AUTOSAR XML (schema 4-0-3)
package /ComponentTypes
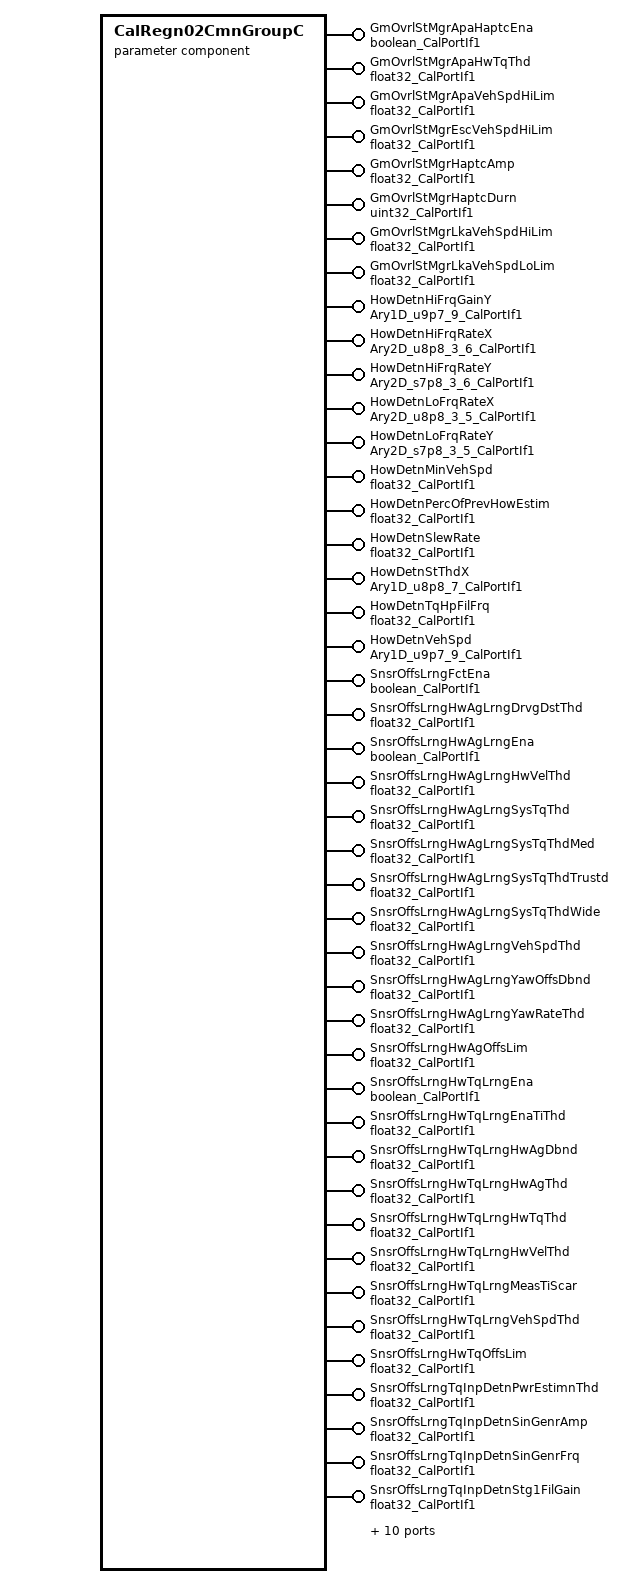
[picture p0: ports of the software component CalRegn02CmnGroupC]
  parameter sw component type CalRegn02CmnGroupC
    54 x provide port:
      GmOvrlStMgrApaHaptcEna: parameter-provide-com-spec{init-value=1, parameter=Logl}, provided-interface=boolean_CalPortIf1
      GmOvrlStMgrApaHwTqThd: parameter-provide-com-spec{init-value=3, parameter=Val}, provided-interface=float32_CalPortIf1
      GmOvrlStMgrApaVehSpdHiLim: parameter-provide-com-spec{init-value=10, parameter=Val}, provided-interface=float32_CalPortIf1
      GmOvrlStMgrEscVehSpdHiLim: parameter-provide-com-spec{init-value=180, parameter=Val}, provided-interface=float32_CalPortIf1
      GmOvrlStMgrHaptcAmp: parameter-provide-com-spec{init-value=0.5, parameter=Val}, provided-interface=float32_CalPortIf1
      GmOvrlStMgrHaptcDurn: parameter-provide-com-spec{init-value=450, parameter=Val}, provided-interface=uint32_CalPortIf1
      GmOvrlStMgrLkaVehSpdHiLim: parameter-provide-com-spec{init-value=180, parameter=Val}, provided-interface=float32_CalPortIf1
      GmOvrlStMgrLkaVehSpdLoLim: parameter-provide-com-spec{init-value=10, parameter=Val}, provided-interface=float32_CalPortIf1
      HowDetnHiFrqGainY: parameter-provide-com-spec{init-value=9 x 2227, parameter=Ary1D}, provided-interface=Ary1D_u9p7_9_CalPortIf1
      HowDetnHiFrqRateX: parameter-provide-com-spec{init-value=[[0, 26, 64, 77, 128, 256], [0, 26, 64, 77, 128, 256], [0, 26, 64, 77, 128, 256]], parameter=Ary2D}, provided-interface=Ary2D_u8p8_3_6_CalPortIf1
      HowDetnHiFrqRateY: parameter-provide-com-spec{init-value=[[-1280, -256, 0, 0, 5120, 5120], [-1280, -256, 0, 0, 5120, 5120], [-1280, -256, 0, 0, 5120, 5120]], parameter=Ary2D}, provided-interface=Ary2D_s7p8_3_6_CalPortIf1
      HowDetnLoFrqRateX: parameter-provide-com-spec{init-value=[[0, 19, 51, 64, 256], [0, 19, 51, 64, 256], [0, 19, 51, 64, 256]], parameter=Ary2D}, provided-interface=Ary2D_u8p8_3_5_CalPortIf1
      HowDetnLoFrqRateY: parameter-provide-com-spec{init-value=[[-512, -128, 0, 0, 23040], [-512, -128, 0, 0, 23040], [-512, -128, 0, 0, 23040]], parameter=Ary2D}, provided-interface=Ary2D_s7p8_3_5_CalPortIf1
      HowDetnMinVehSpd: parameter-provide-com-spec{init-value=10, parameter=Val}, provided-interface=float32_CalPortIf1
      HowDetnPercOfPrevHowEstim: parameter-provide-com-spec{init-value=0.99, parameter=Val}, provided-interface=float32_CalPortIf1
      HowDetnSlewRate: parameter-provide-com-spec{init-value=2, parameter=Val}, provided-interface=float32_CalPortIf1
      HowDetnStThdX: parameter-provide-com-spec{init-value=[0, 15, 64, 90, 166, 192, 241], parameter=Ary1D}, provided-interface=Ary1D_u8p8_7_CalPortIf1
      HowDetnTqHpFilFrq: parameter-provide-com-spec{init-value=7, parameter=Val}, provided-interface=float32_CalPortIf1
      HowDetnVehSpd: parameter-provide-com-spec{init-value=[1280, 2560, 3840, 5120, 6400, 7680, 8960, 10240, 12800], parameter=Ary1D}, provided-interface=Ary1D_u9p7_9_CalPortIf1
      SnsrOffsLrngFctEna: parameter-provide-com-spec{init-value=0, parameter=Logl}, provided-interface=boolean_CalPortIf1
      SnsrOffsLrngHwAgLrngDrvgDstThd: parameter-provide-com-spec{init-value=30, parameter=Val}, provided-interface=float32_CalPortIf1
      SnsrOffsLrngHwAgLrngEna: parameter-provide-com-spec{init-value=0, parameter=Logl}, provided-interface=boolean_CalPortIf1
      SnsrOffsLrngHwAgLrngHwVelThd: parameter-provide-com-spec{init-value=0.25, parameter=Val}, provided-interface=float32_CalPortIf1
      SnsrOffsLrngHwAgLrngSysTqThd: parameter-provide-com-spec{init-value=30, parameter=Val}, provided-interface=float32_CalPortIf1
      SnsrOffsLrngHwAgLrngSysTqThdMed: parameter-provide-com-spec{init-value=3, parameter=Val}, provided-interface=float32_CalPortIf1
      SnsrOffsLrngHwAgLrngSysTqThdTrustd: parameter-provide-com-spec{init-value=1, parameter=Val}, provided-interface=float32_CalPortIf1
      SnsrOffsLrngHwAgLrngSysTqThdWide: parameter-provide-com-spec{init-value=20, parameter=Val}, provided-interface=float32_CalPortIf1
      SnsrOffsLrngHwAgLrngVehSpdThd: parameter-provide-com-spec{init-value=60, parameter=Val}, provided-interface=float32_CalPortIf1
      SnsrOffsLrngHwAgLrngYawOffsDbnd: parameter-provide-com-spec{init-value=0.1, parameter=Val}, provided-interface=float32_CalPortIf1
      SnsrOffsLrngHwAgLrngYawRateThd: parameter-provide-com-spec{init-value=0, parameter=Val}, provided-interface=float32_CalPortIf1
      SnsrOffsLrngHwAgOffsLim: parameter-provide-com-spec{init-value=5, parameter=Val}, provided-interface=float32_CalPortIf1
      SnsrOffsLrngHwTqLrngEna: parameter-provide-com-spec{init-value=0, parameter=Logl}, provided-interface=boolean_CalPortIf1
      SnsrOffsLrngHwTqLrngEnaTiThd: parameter-provide-com-spec{init-value=500, parameter=Val}, provided-interface=float32_CalPortIf1
      SnsrOffsLrngHwTqLrngHwAgDbnd: parameter-provide-com-spec{init-value=0.2, parameter=Val}, provided-interface=float32_CalPortIf1
      SnsrOffsLrngHwTqLrngHwAgThd: parameter-provide-com-spec{init-value=45, parameter=Val}, provided-interface=float32_CalPortIf1
      SnsrOffsLrngHwTqLrngHwTqThd: parameter-provide-com-spec{init-value=1.5, parameter=Val}, provided-interface=float32_CalPortIf1
      SnsrOffsLrngHwTqLrngHwVelThd: parameter-provide-com-spec{init-value=0.15, parameter=Val}, provided-interface=float32_CalPortIf1
      SnsrOffsLrngHwTqLrngMeasTiScar: parameter-provide-com-spec{init-value=1, parameter=Val}, provided-interface=float32_CalPortIf1
      SnsrOffsLrngHwTqLrngVehSpdThd: parameter-provide-com-spec{init-value=0, parameter=Val}, provided-interface=float32_CalPortIf1
      SnsrOffsLrngHwTqOffsLim: parameter-provide-com-spec{init-value=1.5, parameter=Val}, provided-interface=float32_CalPortIf1
      SnsrOffsLrngTqInpDetnPwrEstimnThd: parameter-provide-com-spec{init-value=0, parameter=Val}, provided-interface=float32_CalPortIf1
      SnsrOffsLrngTqInpDetnSinGenrAmp: parameter-provide-com-spec{init-value=0.1, parameter=Val}, provided-interface=float32_CalPortIf1
      SnsrOffsLrngTqInpDetnSinGenrFrq: parameter-provide-com-spec{init-value=27.78, parameter=Val}, provided-interface=float32_CalPortIf1
      SnsrOffsLrngTqInpDetnStg1FilGain: parameter-provide-com-spec{init-value=1.879385242, parameter=Val}, provided-interface=float32_CalPortIf1
      SnsrOffsLrngTqInpDetnStg1WinSize: parameter-provide-com-spec{init-value=18, parameter=Val}, provided-interface=uint8_CalPortIf1
      SnsrOffsLrngTqInpDetnStg2FilGainCen: parameter-provide-com-spec{init-value=1.879385242, parameter=Val}, provided-interface=float32_CalPortIf1
      SnsrOffsLrngTqInpDetnStg2FilGainDwn: parameter-provide-com-spec{init-value=1.891037151, parameter=Val}, provided-interface=float32_CalPortIf1
      SnsrOffsLrngTqInpDetnStg2FilGainUp: parameter-provide-com-spec{init-value=1.867160853, parameter=Val}, provided-interface=float32_CalPortIf1
      SnsrOffsLrngTqInpDetnStg2WinSize: parameter-provide-com-spec{init-value=360, parameter=Val}, provided-interface=uint16_CalPortIf1
      SnsrOffsLrngYawLrngEna: parameter-provide-com-spec{init-value=0, parameter=Logl}, provided-interface=boolean_CalPortIf1
      SnsrOffsLrngYawLrngHwAgThd: parameter-provide-com-spec{init-value=15, parameter=Val}, provided-interface=float32_CalPortIf1
      SnsrOffsLrngYawLrngYawAThd: parameter-provide-com-spec{init-value=2, parameter=Val}, provided-interface=float32_CalPortIf1
      SnsrOffsLrngYawOffsFrshTiThd: parameter-provide-com-spec{init-value=720, parameter=Val}, provided-interface=float32_CalPortIf1
      SnsrOffsLrngYawRateOffsLim: parameter-provide-com-spec{init-value=5, parameter=Val}, provided-interface=float32_CalPortIf1
